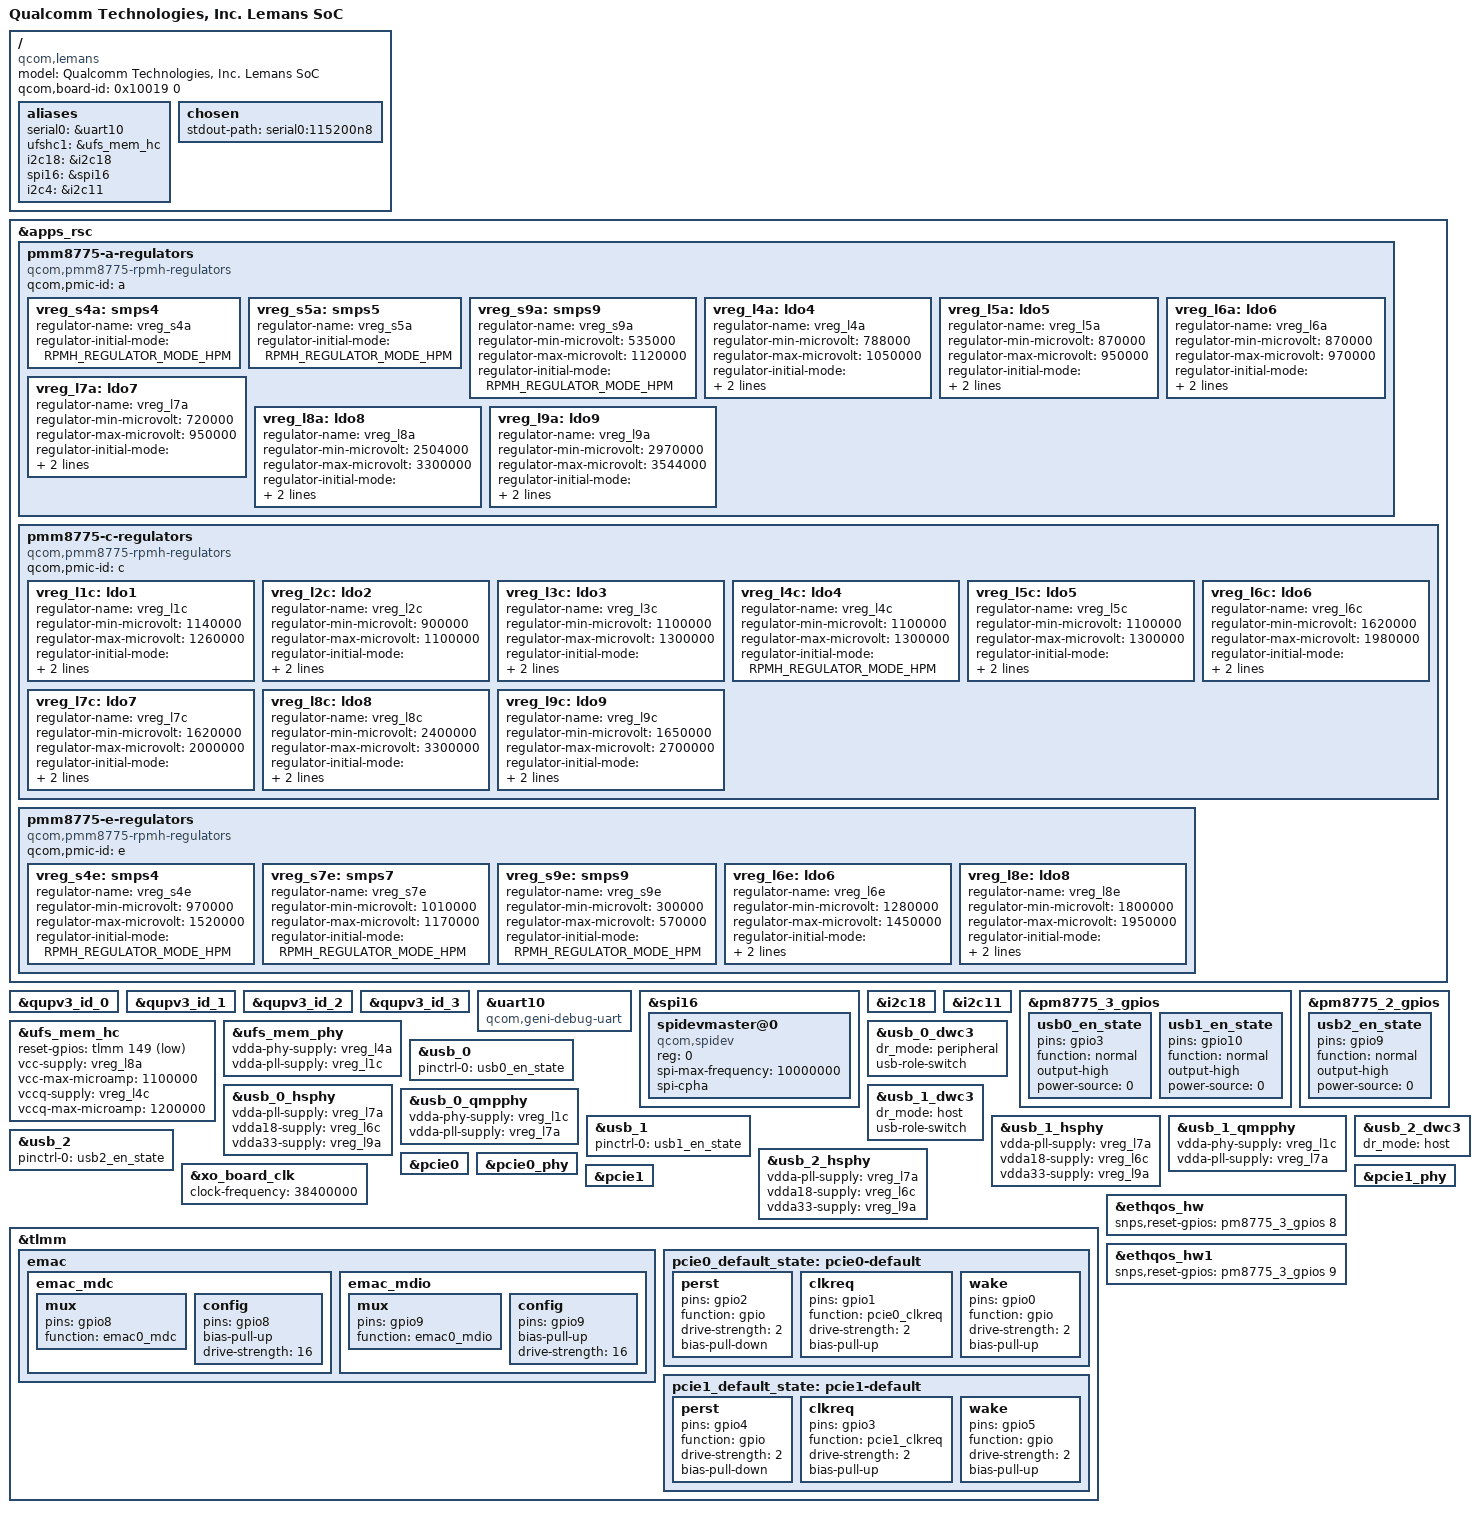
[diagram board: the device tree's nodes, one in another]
// SPDX-License-Identifier: GPL-2.0-only
/*
 * Copyright (c) 2022 Qualcomm Innovation Center, Inc. All rights reserved.
 */

/dts-v1/;

#include <dt-bindings/gpio/gpio.h>
#include <dt-bindings/regulator/qcom,rpmh-regulator.h>
#include <dt-bindings/spmi/spmi.h>

#include "lemans.dtsi"
#include "lemans-pmic-overlay.dtsi"

/ {
	model = "Qualcomm Technologies, Inc. Lemans SoC";
	compatible = "qcom,lemans";
	qcom,board-id = <0x10019 0>;

	aliases {
		serial0 = &uart10;
		ufshc1  = &ufs_mem_hc;
		i2c18   = &i2c18;
		spi16   = &spi16;
		i2c4 = &i2c11;
	};

	chosen {
		stdout-path = "serial0:115200n8";
	};
};

&apps_rsc {
	pmm8775-a-regulators {
		compatible = "qcom,pmm8775-rpmh-regulators";
		qcom,pmic-id = "a";

		vreg_s4a: smps4 {
			regulator-name = "vreg_s4a";
			//regulator-min-microvolt = <1620000>; //FIXME:
			//regulator-max-microvolt = <2000000>; //FIXME:
			regulator-initial-mode = <RPMH_REGULATOR_MODE_HPM>;
		};

		vreg_s5a: smps5 {
			regulator-name = "vreg_s5a";
			//regulator-min-microvolt = <1850000>; //FIXME:
			//regulator-max-microvolt = <2100000>; //FIXME:
			regulator-initial-mode = <RPMH_REGULATOR_MODE_HPM>;
		};

		vreg_s9a: smps9 {
			regulator-name = "vreg_s9a";
			regulator-min-microvolt = <535000>;
			regulator-max-microvolt = <1120000>;
			regulator-initial-mode = <RPMH_REGULATOR_MODE_HPM>;
		};

		vreg_l4a: ldo4 {
			regulator-name = "vreg_l4a";
			regulator-min-microvolt = <788000>;
			regulator-max-microvolt = <1050000>;
			regulator-initial-mode = <RPMH_REGULATOR_MODE_HPM>;
			regulator-allow-set-load;
		};

		vreg_l5a: ldo5 {
			regulator-name = "vreg_l5a";
			regulator-min-microvolt = <870000>;
			regulator-max-microvolt = <950000>;
			regulator-initial-mode = <RPMH_REGULATOR_MODE_HPM>;
			regulator-allow-set-load;
		};

		vreg_l6a: ldo6 {
			regulator-name = "vreg_l6a";
			regulator-min-microvolt = <870000>;
			regulator-max-microvolt = <970000>;
			regulator-initial-mode = <RPMH_REGULATOR_MODE_HPM>;
			regulator-allow-set-load;
		};

		vreg_l7a: ldo7 {
			regulator-name = "vreg_l7a";
			regulator-min-microvolt = <720000>;
			regulator-max-microvolt = <950000>;
			regulator-initial-mode = <RPMH_REGULATOR_MODE_HPM>;
			regulator-allow-set-load;
		};

		vreg_l8a: ldo8 {
			regulator-name = "vreg_l8a";
			regulator-min-microvolt = <2504000>;
			regulator-max-microvolt = <3300000>;
			regulator-initial-mode = <RPMH_REGULATOR_MODE_HPM>;
			regulator-allow-set-load;
		};

		vreg_l9a: ldo9 {
			regulator-name = "vreg_l9a";
			regulator-min-microvolt = <2970000>;
			regulator-max-microvolt = <3544000>;
			regulator-initial-mode = <RPMH_REGULATOR_MODE_HPM>;
			regulator-allow-set-load;
		};
	};

	pmm8775-c-regulators {
		compatible = "qcom,pmm8775-rpmh-regulators";
		qcom,pmic-id = "c";

		vreg_l1c: ldo1 {
			regulator-name = "vreg_l1c";
			regulator-min-microvolt = <1140000>;
			regulator-max-microvolt = <1260000>;
			regulator-initial-mode = <RPMH_REGULATOR_MODE_HPM>;
			regulator-allow-set-load;
		};

		vreg_l2c: ldo2 {
			regulator-name = "vreg_l2c";
			regulator-min-microvolt = <900000>;
			regulator-max-microvolt = <1100000>;
			regulator-initial-mode = <RPMH_REGULATOR_MODE_HPM>;
			regulator-allow-set-load;
		};

		vreg_l3c: ldo3 {
			regulator-name = "vreg_l3c";
			regulator-min-microvolt = <1100000>;
			regulator-max-microvolt = <1300000>;
			regulator-initial-mode = <RPMH_REGULATOR_MODE_HPM>;
			regulator-allow-set-load;
		};

		vreg_l4c: ldo4 {
			regulator-name = "vreg_l4c";
			regulator-min-microvolt = <1100000>;
			regulator-max-microvolt = <1300000>;
			regulator-initial-mode = <RPMH_REGULATOR_MODE_HPM>;
			//regulator-allow-set-load; //FIXME:
		};

		vreg_l5c: ldo5 {
			regulator-name = "vreg_l5c";
			regulator-min-microvolt = <1100000>;
			regulator-max-microvolt = <1300000>;
			regulator-initial-mode = <RPMH_REGULATOR_MODE_HPM>;
			regulator-allow-set-load;
		};

		vreg_l6c: ldo6 {
			regulator-name = "vreg_l6c";
			regulator-min-microvolt = <1620000>;
			regulator-max-microvolt = <1980000>;
			regulator-initial-mode = <RPMH_REGULATOR_MODE_HPM>;
			regulator-allow-set-load;
		};

		vreg_l7c: ldo7 {
			regulator-name = "vreg_l7c";
			regulator-min-microvolt = <1620000>;
			regulator-max-microvolt = <2000000>;
			regulator-initial-mode = <RPMH_REGULATOR_MODE_HPM>;
			regulator-allow-set-load;
		};

		vreg_l8c: ldo8 {
			regulator-name = "vreg_l8c";
			regulator-min-microvolt = <2400000>;
			regulator-max-microvolt = <3300000>;
			regulator-initial-mode = <RPMH_REGULATOR_MODE_HPM>;
			regulator-allow-set-load;
		};

		vreg_l9c: ldo9 {
			regulator-name = "vreg_l9c";
			regulator-min-microvolt = <1650000>;
			regulator-max-microvolt = <2700000>;
			regulator-initial-mode = <RPMH_REGULATOR_MODE_HPM>;
			regulator-allow-set-load;
		};
	};

	pmm8775-e-regulators {
		compatible = "qcom,pmm8775-rpmh-regulators";
		qcom,pmic-id = "e";

		vreg_s4e: smps4 {
			regulator-name = "vreg_s4e";
			regulator-min-microvolt = <970000>;
			regulator-max-microvolt = <1520000>;
			regulator-initial-mode = <RPMH_REGULATOR_MODE_HPM>;
		};

		vreg_s7e: smps7 {
			regulator-name = "vreg_s7e";
			regulator-min-microvolt = <1010000>;
			regulator-max-microvolt = <1170000>;
			regulator-initial-mode = <RPMH_REGULATOR_MODE_HPM>;
		};

		vreg_s9e: smps9 {
			regulator-name = "vreg_s9e";
			regulator-min-microvolt = <300000>;
			regulator-max-microvolt = <570000>;
			regulator-initial-mode = <RPMH_REGULATOR_MODE_HPM>;
		};

		vreg_l6e: ldo6 {
			regulator-name = "vreg_l6e";
			regulator-min-microvolt = <1280000>;
			regulator-max-microvolt = <1450000>;
			regulator-initial-mode = <RPMH_REGULATOR_MODE_HPM>;
			regulator-allow-set-load;
		};

		vreg_l8e: ldo8 {
			regulator-name = "vreg_l8e";
			regulator-min-microvolt = <1800000>;
			regulator-max-microvolt = <1950000>;
			regulator-initial-mode = <RPMH_REGULATOR_MODE_HPM>;
			regulator-allow-set-load;
		};
	};
};

&qupv3_id_0 {
	status = "okay";
};

&qupv3_id_1 {
	status = "okay";
};

&qupv3_id_2 {
	status = "okay";
};

&qupv3_id_3 {
	status = "okay";
};

&uart10 {
	compatible = "qcom,geni-debug-uart";
	status = "okay";
};

&spi16 {
	status = "okay";

	spidevmaster@0 {
		compatible = "qcom,spidev";
		reg = <0>;
		spi-max-frequency = <10000000>;
		spi-cpha;
		status = "okay";
	};
};

&i2c18 {
	status = "okay";
};

&i2c11 {
	status = "okay";
};

&pm8775_3_gpios {
	usb0_en_state: usb0_en_state {
		pins = "gpio3";
		function = "normal";
		output-high;
		power-source = <0>;
	};

	usb1_en_state: usb1_en_state {
		pins = "gpio10";
		function = "normal";
		output-high;
		power-source = <0>;
	};
};

&pm8775_2_gpios {
	usb2_en_state: usb2_en_state {
		pins = "gpio9";
		function = "normal";
		output-high;
		power-source = <0>;
	};
};

&ufs_mem_hc {
	reset-gpios = <&tlmm 149 GPIO_ACTIVE_LOW>;

	vcc-supply = <&vreg_l8a>;
	vcc-max-microamp = <1100000>;
	vccq-supply = <&vreg_l4c>;
	vccq-max-microamp = <1200000>;

	status = "okay";
};

&ufs_mem_phy {
	vdda-phy-supply = <&vreg_l4a>;
	vdda-pll-supply = <&vreg_l1c>;

	status = "okay";
};

&usb_0 {
	pinctrl-names = "default";
	pinctrl-0 = <&usb0_en_state>;

	status = "okay";
};

&usb_0_dwc3 {
	dr_mode = "peripheral";
	usb-role-switch;
};

&usb_0_hsphy {
	vdda-pll-supply = <&vreg_l7a>;
	vdda18-supply = <&vreg_l6c>;
	vdda33-supply = <&vreg_l9a>;

	status = "okay";
};

&usb_0_qmpphy {
	vdda-phy-supply = <&vreg_l1c>;
	vdda-pll-supply = <&vreg_l7a>;

	status = "okay";
};

&usb_1 {
	pinctrl-names = "default";
	pinctrl-0 = <&usb1_en_state>;

	status = "okay";
};

&usb_1_dwc3 {
	dr_mode = "host";
	usb-role-switch;
};

&usb_1_hsphy {
	vdda-pll-supply = <&vreg_l7a>;
	vdda18-supply = <&vreg_l6c>;
	vdda33-supply = <&vreg_l9a>;

	status = "okay";
};

&usb_1_qmpphy {
	vdda-phy-supply = <&vreg_l1c>;
	vdda-pll-supply = <&vreg_l7a>;

	status = "okay";
};

&usb_2 {
	pinctrl-names = "default";
	pinctrl-0 = <&usb2_en_state>;

	status = "okay";
};

&usb_2_dwc3 {
	dr_mode = "host";
};

&usb_2_hsphy {
	vdda-pll-supply = <&vreg_l7a>;
	vdda18-supply = <&vreg_l6c>;
	vdda33-supply = <&vreg_l9a>;

	status = "okay";
};

&xo_board_clk {
	clock-frequency = <38400000>;
};

&pcie0 {
	status = "okay";
};

&pcie0_phy {
	status = "okay";
};

&pcie1 {
	status = "okay";
};

&pcie1_phy {
	status = "okay";
};

&tlmm {
	emac {
		emac_mdc: emac_mdc {
			mux {
				pins = "gpio8";
				function = "emac0_mdc";
			};

			config {
				pins = "gpio8";
				bias-pull-up;
				drive-strength = <16>;
			};
		};

		emac_mdio: emac_mdio {
			mux {
				pins = "gpio9";
				function = "emac0_mdio";
			};

			config {
				pins = "gpio9";
				bias-pull-up;
				drive-strength = <16>;
			};
		};
	};

	pcie0_default_state: pcie0-default {
		perst {
			pins = "gpio2";
			function = "gpio";
			drive-strength = <2>;
			bias-pull-down;
		};

		clkreq {
			pins = "gpio1";
			function = "pcie0_clkreq";
			drive-strength = <2>;
			bias-pull-up;
		};

		wake {
			pins = "gpio0";
			function = "gpio";
			drive-strength = <2>;
			bias-pull-up;
		};
	};

	pcie1_default_state: pcie1-default {
		perst {
			pins = "gpio4";
			function = "gpio";
			drive-strength = <2>;
			bias-pull-down;
		};

		clkreq {
			pins = "gpio3";
			function = "pcie1_clkreq";
			drive-strength = <2>;
			bias-pull-up;
		};

		wake {
			pins = "gpio5";
			function = "gpio";
			drive-strength = <2>;
			bias-pull-up;
		};
	};
};

&ethqos_hw {
	snps,reset-gpios = <&pm8775_3_gpios 8 GPIO_ACTIVE_HIGH>;
};

&ethqos_hw1 {
	snps,reset-gpios = <&pm8775_3_gpios 9 GPIO_ACTIVE_HIGH>;
};
